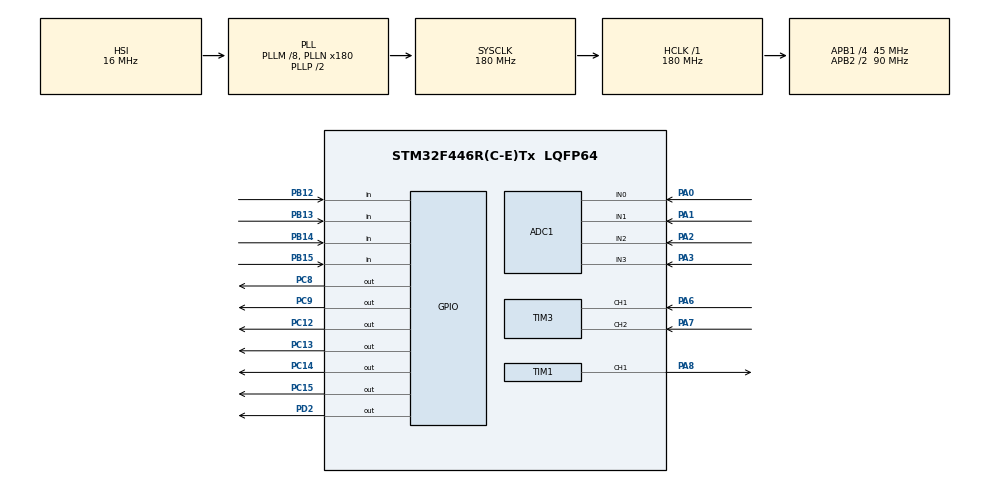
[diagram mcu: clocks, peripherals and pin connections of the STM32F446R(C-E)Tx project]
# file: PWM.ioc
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ADC1.Channel-0\#ChannelRegularConversion=ADC_CHANNEL_0
ADC1.Channel-1\#ChannelRegularConversion=ADC_CHANNEL_1
ADC1.Channel-2\#ChannelRegularConversion=ADC_CHANNEL_2
ADC1.Channel-3\#ChannelRegularConversion=ADC_CHANNEL_3
ADC1.DMAContinuousRequests=ENABLE
ADC1.ExternalTrigConv=ADC_EXTERNALTRIGCONV_T8_TRGO
ADC1.NbrOfConversion=4
ADC1.NbrOfConversionFlag=1
ADC1.Rank-0\#ChannelRegularConversion=1
ADC1.Rank-1\#ChannelRegularConversion=2
ADC1.Rank-2\#ChannelRegularConversion=3
ADC1.Rank-3\#ChannelRegularConversion=4
ADC1.SamplingTime-0\#ChannelRegularConversion=ADC_SAMPLETIME_15CYCLES
ADC1.SamplingTime-1\#ChannelRegularConversion=ADC_SAMPLETIME_15CYCLES
ADC1.SamplingTime-2\#ChannelRegularConversion=ADC_SAMPLETIME_15CYCLES
ADC1.SamplingTime-3\#ChannelRegularConversion=ADC_SAMPLETIME_15CYCLES
ADC1.ScanConvMode=ENABLE
ADC1.master=1
Dma.ADC1.0.Direction=DMA_PERIPH_TO_MEMORY
Dma.ADC1.0.FIFOMode=DMA_FIFOMODE_DISABLE
Dma.ADC1.0.Instance=DMA2_Stream0
Dma.ADC1.0.MemDataAlignment=DMA_MDATAALIGN_WORD
Dma.ADC1.0.MemInc=DMA_MINC_ENABLE
Dma.ADC1.0.Mode=DMA_CIRCULAR
Dma.ADC1.0.PeriphDataAlignment=DMA_PDATAALIGN_WORD
Dma.ADC1.0.PeriphInc=DMA_PINC_DISABLE
Dma.ADC1.0.Priority=DMA_PRIORITY_LOW
Dma.Request0=ADC1
Mcu.Family=STM32F4
Mcu.Name=STM32F446R(C-E)Tx
Mcu.Package=LQFP64
NVIC.ADC_IRQn=true\:0\:0\:false\:false\:true\:true\:true\:true
NVIC.DMA2_Stream0_IRQn=true\:0\:0\:false\:false\:true\:false\:true\:true
NVIC.PriorityGroup=NVIC_PRIORITYGROUP_4
NVIC.TIM1_BRK_TIM9_IRQn=true\:0\:0\:false\:false\:true\:true\:true\:true
NVIC.TIM1_CC_IRQn=true\:0\:0\:false\:false\:true\:true\:true\:true
NVIC.TIM1_TRG_COM_TIM11_IRQn=true\:0\:0\:false\:false\:true\:true\:true\:true
NVIC.TIM1_UP_TIM10_IRQn=true\:0\:0\:false\:false\:true\:true\:true\:true
NVIC.TIM6_DAC_IRQn=true\:0\:0\:false\:false\:true\:true\:true\:true
NVIC.TIM8_UP_TIM13_IRQn=true\:0\:0\:false\:false\:true\:true\:true\:true
PA0-WKUP.Signal=ADCx_IN0
PA1.Signal=ADCx_IN1
PA13.Mode=Serial_Wire
PA13.Signal=SYS_JTMS-SWDIO
PA14.Mode=Serial_Wire
PA14.Signal=SYS_JTCK-SWCLK
PA2.Signal=ADCx_IN2
PA3.Signal=ADCx_IN3
PA6.GPIO_PuPd=GPIO_PULLUP
PA6.Signal=S_TIM3_CH1
PA7.GPIO_PuPd=GPIO_PULLUP
PA7.Signal=S_TIM3_CH2
PA8.Signal=S_TIM1_CH1
PB12.Signal=GPIO_Input
PB13.Signal=GPIO_Input
PB14.Signal=GPIO_Input
PB15.Signal=GPIO_Input
PB8.Signal=S_TIM2_CH1_ETR
PB9.Signal=S_TIM2_CH2
PC12.Signal=GPIO_Output
PC13.Signal=GPIO_Output
PC14-OSC32_IN.Signal=GPIO_Output
PC15-OSC32_OUT.Signal=GPIO_Output
PC8.Signal=GPIO_Output
PC9.Signal=GPIO_Output
PD2.Signal=GPIO_Output
PH0-OSC_IN.Mode=HSE-External-Oscillator
PH0-OSC_IN.Signal=RCC_OSC_IN
PH1-OSC_OUT.Mode=HSE-External-Oscillator
PH1-OSC_OUT.Signal=RCC_OSC_OUT
ProjectManager.HeapSize=0x200
ProjectManager.StackSize=0x400
ProjectManager.TargetToolchain=STM32CubeIDE
RCC.AHBFreq_Value=180000000
RCC.APB1CLKDivider=RCC_HCLK_DIV4
RCC.APB1Freq_Value=45000000
RCC.APB1TimFreq_Value=90000000
RCC.APB2CLKDivider=RCC_HCLK_DIV2
RCC.APB2Freq_Value=90000000
RCC.APB2TimFreq_Value=180000000
RCC.CortexFreq_Value=180000000
RCC.HCLKFreq_Value=180000000
RCC.HSE_VALUE=16000000
RCC.PLLM=8
RCC.PLLN=180
RCC.SYSCLKFreq_VALUE=180000000
RCC.SYSCLKSource=RCC_SYSCLKSOURCE_PLLCLK
RCC.USBFreq_Value=180000000
RCC.VCOOutputFreq_Value=360000000
SH.ADCx_IN0.0=ADC1_IN0,IN0
SH.ADCx_IN1.0=ADC1_IN1,IN1
SH.ADCx_IN2.0=ADC1_IN2,IN2
SH.ADCx_IN3.0=ADC1_IN3,IN3
SH.S_TIM1_CH1.0=TIM1_CH1,PWM Generation1 CH1
SH.S_TIM2_CH1_ETR.0=TIM2_CH1
SH.S_TIM2_CH2.0=TIM2_CH2
SH.S_TIM3_CH1.0=TIM3_CH1,Encoder_Interface
SH.S_TIM3_CH2.0=TIM3_CH2,Encoder_Interface
TIM1.Channel-PWM\ Generation1\ CH1=TIM_CHANNEL_1
TIM1.Period=1000-1
TIM1.Prescaler=9-1
TIM3.EncoderMode=TIM_ENCODERMODE_TI12
TIM3.IC1Filter=5
TIM3.IC2Filter=5
TIM6.Period=5000-1
TIM6.Prescaler=4500-1
TIM8.Period=1000-1
TIM8.Prescaler=180-1
TIM8.TIM_MasterOutputTrigger=TIM_TRGO_UPDATE
VP_TIM6_VS_ClockSourceINT.Mode=Enable_Timer
VP_TIM8_VS_ClockSourceINT.Mode=Internal
board=custom

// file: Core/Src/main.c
/* USER CODE BEGIN Header */
/**
  ******************************************************************************
  * @file           : main.c
  * @brief          : Main program body
  ******************************************************************************
  * @attention
  *
  * Copyright (c) 2024 STMicroelectronics.
  * All rights reserved.
  *
  * This software is licensed under terms that can be found in the LICENSE file
  * in the root directory of this software component.
  * If no LICENSE file comes with this software, it is provided AS-IS.
  *
  ******************************************************************************
  */
/* USER CODE END Header */
#include "main.h"
#include "adc.h"
#include "dma.h"
#include "tim.h"
#include "gpio.h"

void SystemClock_Config(void);

int main(void)
{

  /* MCU Configuration--------------------------------------------------------*/

  /* Reset of all peripherals, Initializes the Flash interface and the Systick. */
  HAL_Init();

  /* Configure the system clock */
  SystemClock_Config();

  /* Initialize all configured peripherals */
  MX_GPIO_Init();
  MX_DMA_Init();
  MX_ADC1_Init();
  MX_TIM8_Init();
  MX_TIM6_Init();
  MX_TIM1_Init();
  MX_TIM3_Init();
  /* USER CODE BEGIN 2 */

  HAL_TIM_PWM_Start(&htim1, TIM_CHANNEL_1);
  HAL_TIMEx_PWMN_Start(&htim1, TIM_CHANNEL_1);

  /* USER CODE END 2 */

  /* Infinite loop */
  while (1)
  {

    /* USER CODE BEGIN 3 */

	  TIM1->CCR1=0;
	  HAL_Delay(1000);

	  TIM1->CCR1=300;
      HAL_Delay(1000);

      TIM1->CCR1=500;
	  HAL_Delay(1000);

	  TIM1->CCR1=700;
	  HAL_Delay(1000);

  }
  /* USER CODE END 3 */
}

void SystemClock_Config(void)
{
  RCC_OscInitTypeDef RCC_OscInitStruct = {0};
  RCC_ClkInitTypeDef RCC_ClkInitStruct = {0};

  /** Configure the main internal regulator output voltage
  */
  __HAL_RCC_PWR_CLK_ENABLE();
  __HAL_PWR_VOLTAGESCALING_CONFIG(PWR_REGULATOR_VOLTAGE_SCALE1);

  /** Initializes the RCC Oscillators according to the specified parameters
  * in the RCC_OscInitTypeDef structure.
  */
  RCC_OscInitStruct.OscillatorType = RCC_OSCILLATORTYPE_HSI;
  RCC_OscInitStruct.HSIState = RCC_HSI_ON;
  RCC_OscInitStruct.HSICalibrationValue = RCC_HSICALIBRATION_DEFAULT;
  RCC_OscInitStruct.PLL.PLLState = RCC_PLL_ON;
  RCC_OscInitStruct.PLL.PLLSource = RCC_PLLSOURCE_HSI;
  RCC_OscInitStruct.PLL.PLLM = 8;
  RCC_OscInitStruct.PLL.PLLN = 180;
  RCC_OscInitStruct.PLL.PLLP = RCC_PLLP_DIV2;
  RCC_OscInitStruct.PLL.PLLQ = 2;
  RCC_OscInitStruct.PLL.PLLR = 2;
  if (HAL_RCC_OscConfig(&RCC_OscInitStruct) != HAL_OK)
  {
    Error_Handler();
  }

  /** Activate the Over-Drive mode
  */
  if (HAL_PWREx_EnableOverDrive() != HAL_OK)
  {
    Error_Handler();
  }

  /** Initializes the CPU, AHB and APB buses clocks
  */
  RCC_ClkInitStruct.ClockType = RCC_CLOCKTYPE_HCLK|RCC_CLOCKTYPE_SYSCLK
                              |RCC_CLOCKTYPE_PCLK1|RCC_CLOCKTYPE_PCLK2;
  RCC_ClkInitStruct.SYSCLKSource = RCC_SYSCLKSOURCE_PLLCLK;
  RCC_ClkInitStruct.AHBCLKDivider = RCC_SYSCLK_DIV1;
  RCC_ClkInitStruct.APB1CLKDivider = RCC_HCLK_DIV4;
  RCC_ClkInitStruct.APB2CLKDivider = RCC_HCLK_DIV2;

  if (HAL_RCC_ClockConfig(&RCC_ClkInitStruct, FLASH_LATENCY_5) != HAL_OK)
  {
    Error_Handler();
  }
}

void Error_Handler(void)
{
  __disable_irq();
  while (1)
  {
  }
}
